# ESP32-H2 register map
Vendor: ESPRESSIF SYSTEMS (SHANGHAI) CO., LTD.; Series: ESP32 H-Series; File version: 12
CPU: RV32IMAC r0p0, little endian, no MPU, no FPU, 0 interrupt priority bits
Address unit: 32 bits
Registers are 32-bit, read-write, reset 0x0 unless marked. A register's access mark holds for its fields unless they carry their own. Offsets are from the block's base; [hi:lo] are bit positions; {n}, {i} and the like mark numbered series.

## EFUSE — eFuse Controller
Base 0x600B0800
0x00 PGM_DATA0 — Register 0 that stores data to be programmed.
  [31:0] PGM_DATA_0 — Configures the 0th 32-bit data to be programmed.
0x04 PGM_DATA1 — Register 1 that stores data to be programmed.
  [31:0] PGM_DATA_1 — Configures the 1st 32-bit data to be programmed.
0x08 PGM_DATA2 — Register 2 that stores data to be programmed.
  [31:0] PGM_DATA_2 — Configures the 2nd 32-bit data to be programmed.
0x0C PGM_DATA3 — Register 3 that stores data to be programmed.
  [31:0] PGM_DATA_3 — Configures the 3rd 32-bit data to be programmed.
{0x0+4i} PGM_DATA{i} (i=4..7) — Register {i} that stores data to be programmed.
  [31:0] PGM_DATA_{i} — Configures the {i}th 32-bit data to be programmed.
0x20 PGM_CHECK_VALUE0 — Register 0 that stores the RS code to be programmed.
  [31:0] PGM_RS_DATA_0 — Configures the 0th 32-bit RS code to be programmed.
0x24 PGM_CHECK_VALUE1 — Register 1 that stores the RS code to be programmed.
  [31:0] PGM_RS_DATA_1 — Configures the 1st 32-bit RS code to be programmed.
0x28 PGM_CHECK_VALUE2 — Register 2 that stores the RS code to be programmed.
  [31:0] PGM_RS_DATA_2 — Configures the 2nd 32-bit RS code to be programmed.
0x2C RD_WR_DIS ro — BLOCK0 data register 0.
  [31:0] WR_DIS — Represents whether programming of individual eFuse memory bit is disabled or enabled. 1: Disabled. 0 Enabled.
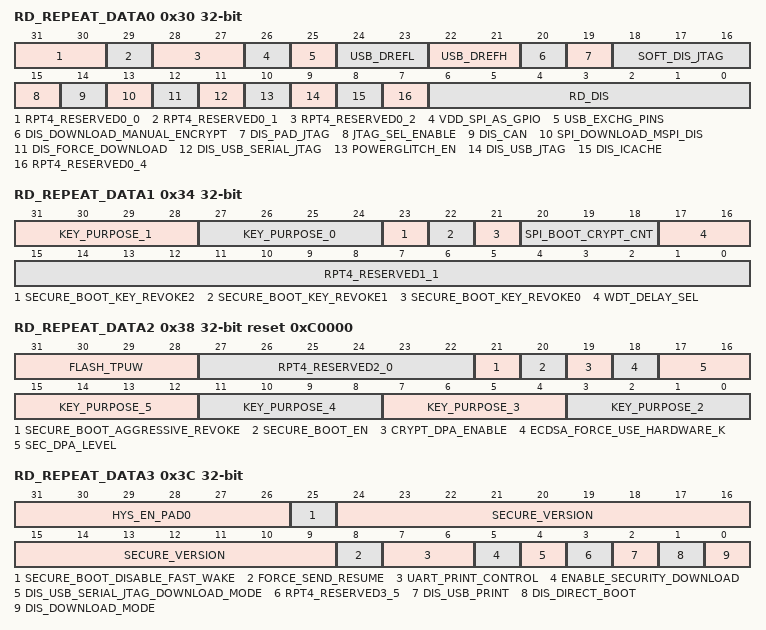
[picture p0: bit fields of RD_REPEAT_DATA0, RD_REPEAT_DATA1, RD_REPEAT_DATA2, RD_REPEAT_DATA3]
0x30 RD_REPEAT_DATA0 ro — BLOCK0 data register 1.
  [31:30] RPT4_RESERVED0_0 — Reserved.
  [29] RPT4_RESERVED0_1 — Reserved.
  [28:27] RPT4_RESERVED0_2 — Reserved.
  [26] VDD_SPI_AS_GPIO — Represents whether vdd spi pin is functioned as gpio. 1: functioned. 0: not functioned.
  [25] USB_EXCHG_PINS — Represents whether the D+ and D- pins is exchanged. 1: exchanged. 0: not exchanged.
  [24:23] USB_DREFL — Represents the single-end input threhold vrefl, 1.76 V to 2 V with step of 80 mV.
  [22:21] USB_DREFH — Represents the single-end input threhold vrefh, 1.76 V to 2 V with step of 80 mV.
  [20] DIS_DOWNLOAD_MANUAL_ENCRYPT — Represents whether flash encrypt function is disabled or enabled(except in SPI boot mode). 1: disabled. 0: enabled.
  [19] DIS_PAD_JTAG — Represents whether JTAG is disabled in the hard way(permanently). 1: disabled. 0: enabled.
  [18:16] SOFT_DIS_JTAG — Represents whether JTAG is disabled in soft way. Odd number: disabled. Even number: enabled.
  [15] JTAG_SEL_ENABLE — Represents whether the selection between usb_to_jtag and pad_to_jtag through strapping gpio15 when both EFUSE_DIS_PAD_JTAG and EFUSE_DIS_USB_JTAG are equal to 0 is enabled or disabled. 1: enabled. 0: disabled.
  [14] DIS_CAN — Represents whether TWAI function is disabled or enabled. 1: disabled. 0: enabled.
  [13] SPI_DOWNLOAD_MSPI_DIS — Represents whether SPI0 controller during boot_mode_download is disabled or enabled. 1: disabled. 0: enabled.
  [12] DIS_FORCE_DOWNLOAD — Represents whether the function that forces chip into download mode is disabled or enabled. 1: disabled. 0: enabled.
  [11] DIS_USB_SERIAL_JTAG — Represents whether USB-Serial-JTAG is disabled or enabled. 1: disabled. 0: enabled.
  [10] POWERGLITCH_EN — Represents whether power glitch function is enabled. 1: enabled. 0: disabled.
  [9] DIS_USB_JTAG — Represents whether the function of usb switch to jtag is disabled or enabled. 1: disabled. 0: enabled.
  [8] DIS_ICACHE — Represents whether icache is disabled or enabled. 1: disabled. 0: enabled.
  [7] RPT4_RESERVED0_4 — Reserved.
  [6:0] RD_DIS — Represents whether reading of individual eFuse block(block4~block10) is disabled or enabled. 1: disabled. 0: enabled.
0x34 RD_REPEAT_DATA1 ro — BLOCK0 data register 2.
  [31:28] KEY_PURPOSE_1 — Represents the purpose of Key1.
  [27:24] KEY_PURPOSE_0 — Represents the purpose of Key0.
  [23] SECURE_BOOT_KEY_REVOKE2 — Represents whether revoking third secure boot key is enabled or disabled. 1: enabled. 0: disabled.
  [22] SECURE_BOOT_KEY_REVOKE1 — Represents whether revoking second secure boot key is enabled or disabled. 1: enabled. 0: disabled.
  [21] SECURE_BOOT_KEY_REVOKE0 — Represents whether revoking first secure boot key is enabled or disabled. 1: enabled. 0: disabled.
  [20:18] SPI_BOOT_CRYPT_CNT — Represents whether SPI boot encrypt/decrypt is disabled or enabled. Odd number of 1: enabled. Even number of 1: disabled.
  [17:16] WDT_DELAY_SEL — Represents whether RTC watchdog timeout threshold is selected at startup. 1: selected. 0: not selected.
  [15:0] RPT4_RESERVED1_1 — Reserved.
0x38 RD_REPEAT_DATA2 ro reset 0xC0000 — BLOCK0 data register 3.
  [31:28] FLASH_TPUW — Represents the flash waiting time after power-up, in unit of ms. When the value less than 15, the waiting time is the programmed value. Otherwise, the waiting time is 2 times the programmed value.
  [27:22] RPT4_RESERVED2_0 — Reserved.
  [21] SECURE_BOOT_AGGRESSIVE_REVOKE — Represents whether revoking aggressive secure boot is enabled or disabled. 1: enabled. 0: disabled.
  [20] SECURE_BOOT_EN — Represents whether secure boot is enabled or disabled. 1: enabled. 0: disabled.
  [19] CRYPT_DPA_ENABLE — Represents whether anti-dpa attack is enabled. 1:enabled. 0: disabled.
  [18] ECDSA_FORCE_USE_HARDWARE_K — Represents whether hardware random number k is forced used in ESDCA. 1: force used. 0: not force used.
  [17:16] SEC_DPA_LEVEL — Represents the spa secure level by configuring the clock random divide mode.
  [4n-5:4n-8] KEY_PURPOSE_{n} (n=2..5) — Represents the purpose of Key{n}.
0x3C RD_REPEAT_DATA3 ro — BLOCK0 data register 4.
  [31:26] HYS_EN_PAD0 — Represents whether the hysteresis function of corresponding PAD is enabled. 1: enabled. 0:disabled.
  [25] SECURE_BOOT_DISABLE_FAST_WAKE — Represents whether FAST VERIFY ON WAKE is disabled or enabled when Secure Boot is enabled. 1: disabled. 0: enabled.
  [24:9] SECURE_VERSION — Represents the version used by ESP-IDF anti-rollback feature.
  [8] FORCE_SEND_RESUME — Represents whether ROM code is forced to send a resume command during SPI boot. 1: forced. 0:not forced.
  [7:6] UART_PRINT_CONTROL — Represents the type of UART printing. 00: force enable printing. 01: enable printing when GPIO8 is reset at low level. 10: enable printing when GPIO8 is reset at high level. 11: force disable printing.
  [5] ENABLE_SECURITY_DOWNLOAD — Represents whether security download is enabled or disabled. 1: enabled. 0: disabled.
  [4] DIS_USB_SERIAL_JTAG_DOWNLOAD_MODE — Represents whether the USB-Serial-JTAG download function is disabled or enabled. 1: disabled. 0: enabled.
  [3] RPT4_RESERVED3_5 — Reserved.
  [2] DIS_USB_PRINT — Represents whether print from USB-Serial-JTAG is disabled or enabled. 1: disabled. 0: enabled.
  [1] DIS_DIRECT_BOOT — Represents whether direct boot mode is disabled or enabled. 1: disabled. 0: enabled.
  [0] DIS_DOWNLOAD_MODE — Represents whether Download mode is disabled or enabled. 1: disabled. 0: enabled.
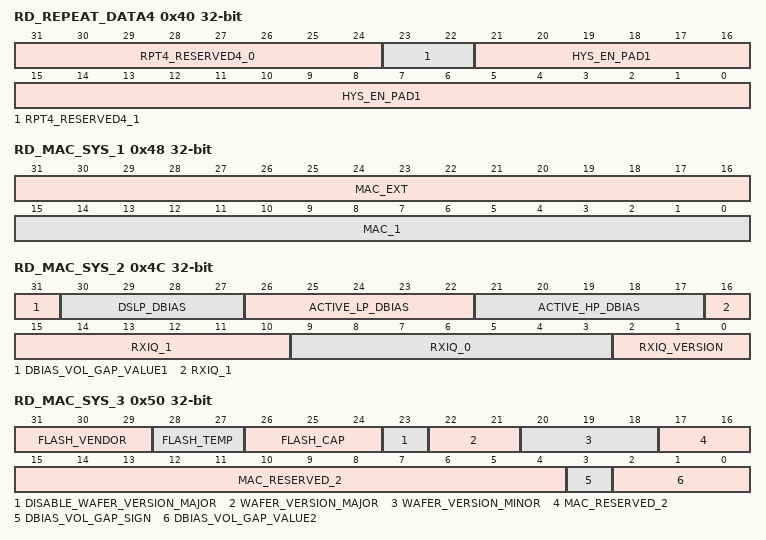
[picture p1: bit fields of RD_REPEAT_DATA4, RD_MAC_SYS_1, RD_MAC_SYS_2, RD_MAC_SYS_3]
0x40 RD_REPEAT_DATA4 ro — BLOCK0 data register 5.
  [31:24] RPT4_RESERVED4_0 — Reserved.
  [23:22] RPT4_RESERVED4_1 — Reserved.
  [21:0] HYS_EN_PAD1 — Represents whether the hysteresis function of corresponding PAD is enabled. 1: enabled. 0:disabled.
0x44 RD_MAC_SYS_0 ro — BLOCK1 data register $n.
  [31:0] MAC_0 — Stores the low 32 bits of MAC address.
0x48 RD_MAC_SYS_1 ro — BLOCK1 data register $n.
  [31:16] MAC_EXT — Stores the extended bits of MAC address.
  [15:0] MAC_1 — Stores the high 16 bits of MAC address.
0x4C RD_MAC_SYS_2 ro — BLOCK1 data register $n.
  [31] DBIAS_VOL_GAP_VALUE1 — Stores the low 1 bit of dbias_vol_gap.
  [30:27] DSLP_DBIAS — Stores the PMU sleep dbias.
  [26:22] ACTIVE_LP_DBIAS — Stores the PMU active lp dbias.
  [21:17] ACTIVE_HP_DBIAS — Stores the PMU active hp dbias.
  [16:10] RXIQ_1 — Stores RF Calibration data. RXIQ data 1.
  [9:3] RXIQ_0 — Stores RF Calibration data. RXIQ data 0.
  [2:0] RXIQ_VERSION — Stores RF Calibration data. RXIQ version.
0x50 RD_MAC_SYS_3 ro — BLOCK1 data register $n.
  [31:29] FLASH_VENDOR — Stores the flash vendor.
  [28:27] FLASH_TEMP — Stores the flash temp.
  [26:24] FLASH_CAP — Stores the flash cap.
  [23] DISABLE_WAFER_VERSION_MAJOR — Disables check of wafer version major.
  [22:21] WAFER_VERSION_MAJOR — Stores the wafer version major.
  [20:18] WAFER_VERSION_MINOR — Stores the wafer version minor.
  [17:4] MAC_RESERVED_2 — Reserved.
  [3] DBIAS_VOL_GAP_SIGN — Stores the sign bit of dbias_vol_gap.
  [2:0] DBIAS_VOL_GAP_VALUE2 — Stores the high 3 bits of dbias_vol_gap.
0x54 RD_MAC_SYS_4 ro — BLOCK1 data register $n.
  [31:0] SYS_DATA_PART0_1 — Stores the first 32 bits of the zeroth part of system data.
0x58 RD_MAC_SYS_5 ro — BLOCK1 data register $n.
  [31:0] SYS_DATA_PART0_2 — Stores the second 32 bits of the zeroth part of system data.
0x5C RD_SYS_PART1_DATA0 ro — Register $n of BLOCK2 (system).
  [31:0] SYS_DATA_PART1_0 — Stores the zeroth 32 bits of the first part of system data.
0x60 RD_SYS_PART1_DATA1 ro — Register $n of BLOCK2 (system).
  [31:0] SYS_DATA_PART1_1 — Stores the first 32 bits of the first part of system data.
0x64 RD_SYS_PART1_DATA2 ro — Register $n of BLOCK2 (system).
  [31:0] SYS_DATA_PART1_2 — Stores the second 32 bits of the first part of system data.
0x68 RD_SYS_PART1_DATA3 ro — Register $n of BLOCK2 (system).
  [31:0] SYS_DATA_PART1_3 — Stores the third 32 bits of the first part of system data.
0x6C RD_SYS_PART1_DATA4 ro — Register $n of BLOCK2 (system).
  [31:0] SYS_DATA_PART1_4 — Stores the fourth 32 bits of the first part of system data.
0x70 RD_SYS_PART1_DATA5 ro — Register $n of BLOCK2 (system).
  [31:0] SYS_DATA_PART1_5 — Stores the fifth 32 bits of the first part of system data.
0x74 RD_SYS_PART1_DATA6 ro — Register $n of BLOCK2 (system).
  [31:0] SYS_DATA_PART1_6 — Stores the sixth 32 bits of the first part of system data.
0x78 RD_SYS_PART1_DATA7 ro — Register $n of BLOCK2 (system).
  [31:0] SYS_DATA_PART1_7 — Stores the seventh 32 bits of the first part of system data.
0x7C RD_USR_DATA0 ro — Register $n of BLOCK3 (user).
  [31:0] USR_DATA0 — Stores the zeroth 32 bits of BLOCK3 (user).
0x80 RD_USR_DATA1 ro — Register $n of BLOCK3 (user).
  [31:0] USR_DATA1 — Stores the first 32 bits of BLOCK3 (user).
0x84 RD_USR_DATA2 ro — Register $n of BLOCK3 (user).
  [31:0] USR_DATA2 — Stores the second 32 bits of BLOCK3 (user).
0x88 RD_USR_DATA3 ro — Register $n of BLOCK3 (user).
  [31:0] USR_DATA3 — Stores the third 32 bits of BLOCK3 (user).
0x8C RD_USR_DATA4 ro — Register $n of BLOCK3 (user).
  [31:0] USR_DATA4 — Stores the fourth 32 bits of BLOCK3 (user).
0x90 RD_USR_DATA5 ro — Register $n of BLOCK3 (user).
  [31:0] USR_DATA5 — Stores the fifth 32 bits of BLOCK3 (user).
0x94 RD_USR_DATA6 ro — Register $n of BLOCK3 (user).
  [31:0] USR_DATA6 — Stores the sixth 32 bits of BLOCK3 (user).
0x98 RD_USR_DATA7 ro — Register $n of BLOCK3 (user).
  [31:0] USR_DATA7 — Stores the seventh 32 bits of BLOCK3 (user).
{0x9C+0x20*i} RD_KEY{i}_DATA0 ro (i=0..5) — Register $n of BLOCK{i+4} (KEY{i}).
  [31:0] KEY{i}_DATA0 — Stores the zeroth 32 bits of KEY{i}.
{0xA0+0x20*i} RD_KEY{i}_DATA1 ro (i=0..5) — Register $n of BLOCK{i+4} (KEY{i}).
  [31:0] KEY{i}_DATA1 — Stores the first 32 bits of KEY{i}.
{0xA4+0x20*i} RD_KEY{i}_DATA2 ro (i=0..5) — Register $n of BLOCK{i+4} (KEY{i}).
  [31:0] KEY{i}_DATA2 — Stores the second 32 bits of KEY{i}.
{0xA8+0x20*i} RD_KEY{i}_DATA3 ro (i=0..5) — Register $n of BLOCK{i+4} (KEY{i}).
  [31:0] KEY{i}_DATA3 — Stores the third 32 bits of KEY{i}.
{0xAC+0x20*i} RD_KEY{i}_DATA4 ro (i=0..5) — Register $n of BLOCK{i+4} (KEY{i}).
  [31:0] KEY{i}_DATA4 — Stores the fourth 32 bits of KEY{i}.
{0xB0+0x20*i} RD_KEY{i}_DATA5 ro (i=0..5) — Register $n of BLOCK{i+4} (KEY{i}).
  [31:0] KEY{i}_DATA5 — Stores the fifth 32 bits of KEY{i}.
{0xB4+0x20*i} RD_KEY{i}_DATA6 ro (i=0..5) — Register $n of BLOCK{i+4} (KEY{i}).
  [31:0] KEY{i}_DATA6 — Stores the sixth 32 bits of KEY{i}.
{0xB8+0x20*i} RD_KEY{i}_DATA7 ro (i=0..5) — Register $n of BLOCK{i+4} (KEY{i}).
  [31:0] KEY{i}_DATA7 — Stores the seventh 32 bits of KEY{i}.
0x15C RD_SYS_PART2_DATA0 ro — Register $n of BLOCK10 (system).
  [31:0] SYS_DATA_PART2_0 — Stores the 0th 32 bits of the 2nd part of system data.
0x160 RD_SYS_PART2_DATA1 ro — Register $n of BLOCK9 (KEY5).
  [31:0] SYS_DATA_PART2_1 — Stores the 0th 32 bits of the 2nd part of system data.
{0x15C+4i} RD_SYS_PART2_DATA{i} ro (i=2..7) — Register $n of BLOCK10 (system).
  [31:0] SYS_DATA_PART2_{i} — Stores the 0th 32 bits of the 2nd part of system data.
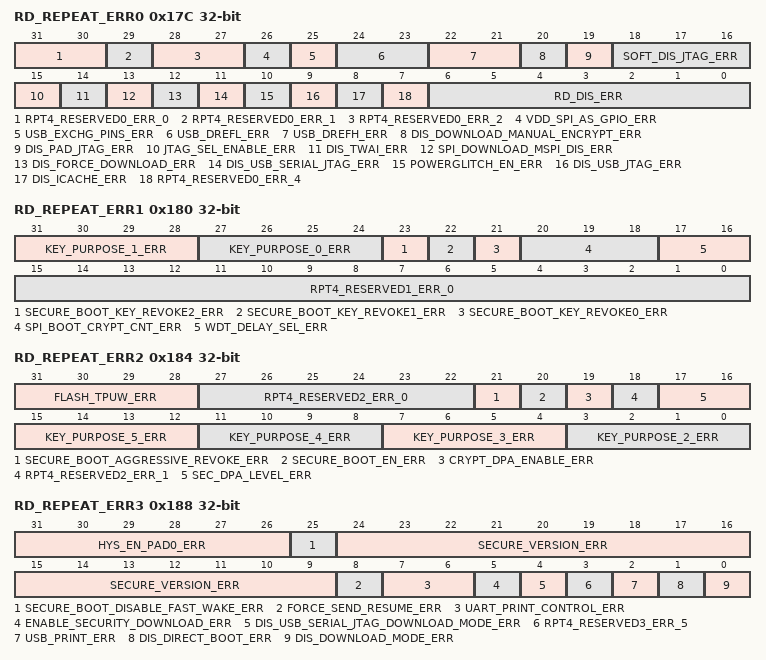
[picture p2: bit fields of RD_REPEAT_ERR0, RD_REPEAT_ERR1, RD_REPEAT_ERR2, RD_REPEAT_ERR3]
0x17C RD_REPEAT_ERR0 ro — Programming error record register 0 of BLOCK0.
  [31:30] RPT4_RESERVED0_ERR_0 — Reserved.
  [29] RPT4_RESERVED0_ERR_1 — Reserved.
  [28:27] RPT4_RESERVED0_ERR_2 — Reserved.
  [26] VDD_SPI_AS_GPIO_ERR — Indicates a programming error of VDD_SPI_AS_GPIO.
  [25] USB_EXCHG_PINS_ERR — Indicates a programming error of USB_EXCHG_PINS.
  [24:23] USB_DREFL_ERR — Indicates a programming error of USB_DREFL.
  [22:21] USB_DREFH_ERR — Indicates a programming error of USB_DREFH.
  [20] DIS_DOWNLOAD_MANUAL_ENCRYPT_ERR — Indicates a programming error of DIS_DOWNLOAD_MANUAL_ENCRYPT.
  [19] DIS_PAD_JTAG_ERR — Indicates a programming error of DIS_PAD_JTAG.
  [18:16] SOFT_DIS_JTAG_ERR — Indicates a programming error of SOFT_DIS_JTAG.
  [15] JTAG_SEL_ENABLE_ERR — Indicates a programming error of JTAG_SEL_ENABLE.
  [14] DIS_TWAI_ERR — Indicates a programming error of DIS_CAN.
  [13] SPI_DOWNLOAD_MSPI_DIS_ERR — Indicates a programming error of SPI_DOWNLOAD_MSPI_DIS.
  [12] DIS_FORCE_DOWNLOAD_ERR — Indicates a programming error of DIS_FORCE_DOWNLOAD.
  [11] DIS_USB_SERIAL_JTAG_ERR — Indicates a programming error of DIS_USB_DEVICE.
  [10] POWERGLITCH_EN_ERR — Indicates a programming error of POWERGLITCH_EN.
  [9] DIS_USB_JTAG_ERR — Indicates a programming error of DIS_USB_JTAG.
  [8] DIS_ICACHE_ERR — Indicates a programming error of DIS_ICACHE.
  [7] RPT4_RESERVED0_ERR_4 — Reserved.
  [6:0] RD_DIS_ERR — Indicates a programming error of RD_DIS.
0x180 RD_REPEAT_ERR1 ro — Programming error record register 1 of BLOCK0.
  [31:28] KEY_PURPOSE_1_ERR — Indicates a programming error of KEY_PURPOSE_1.
  [27:24] KEY_PURPOSE_0_ERR — Indicates a programming error of KEY_PURPOSE_0.
  [23] SECURE_BOOT_KEY_REVOKE2_ERR — Indicates a programming error of SECURE_BOOT_KEY_REVOKE2.
  [22] SECURE_BOOT_KEY_REVOKE1_ERR — Indicates a programming error of SECURE_BOOT_KEY_REVOKE1.
  [21] SECURE_BOOT_KEY_REVOKE0_ERR — Indicates a programming error of SECURE_BOOT_KEY_REVOKE0.
  [20:18] SPI_BOOT_CRYPT_CNT_ERR — Indicates a programming error of SPI_BOOT_CRYPT_CNT.
  [17:16] WDT_DELAY_SEL_ERR — Indicates a programming error of WDT_DELAY_SEL.
  [15:0] RPT4_RESERVED1_ERR_0 — Reserved.
0x184 RD_REPEAT_ERR2 ro — Programming error record register 2 of BLOCK0.
  [31:28] FLASH_TPUW_ERR — Indicates a programming error of FLASH_TPUW.
  [27:22] RPT4_RESERVED2_ERR_0 — Reserved.
  [21] SECURE_BOOT_AGGRESSIVE_REVOKE_ERR — Indicates a programming error of SECURE_BOOT_AGGRESSIVE_REVOKE.
  [20] SECURE_BOOT_EN_ERR — Indicates a programming error of SECURE_BOOT_EN.
  [19] CRYPT_DPA_ENABLE_ERR — Indicates a programming error of CRYPT_DPA_ENABLE.
  [18] RPT4_RESERVED2_ERR_1 — Reserved.
  [17:16] SEC_DPA_LEVEL_ERR — Indicates a programming error of SEC_DPA_LEVEL.
  [4n-5:4n-8] KEY_PURPOSE_{n}_ERR (n=2..5) — Indicates a programming error of KEY_PURPOSE_{n}.
0x188 RD_REPEAT_ERR3 ro — Programming error record register 3 of BLOCK0.
  [31:26] HYS_EN_PAD0_ERR — Indicates a programming error of HYS_EN_PAD0.
  [25] SECURE_BOOT_DISABLE_FAST_WAKE_ERR — Indicates a programming error of SECURE_BOOT_DISABLE_FAST_WAKE.
  [24:9] SECURE_VERSION_ERR — Indicates a programming error of SECURE VERSION.
  [8] FORCE_SEND_RESUME_ERR — Indicates a programming error of FORCE_SEND_RESUME.
  [7:6] UART_PRINT_CONTROL_ERR — Indicates a programming error of UART_PRINT_CONTROL.
  [5] ENABLE_SECURITY_DOWNLOAD_ERR — Indicates a programming error of ENABLE_SECURITY_DOWNLOAD.
  [4] DIS_USB_SERIAL_JTAG_DOWNLOAD_MODE_ERR — Indicates a programming error of DIS_USB_SERIAL_JTAG_DOWNLOAD_MODE.
  [3] RPT4_RESERVED3_ERR_5 — Reserved.
  [2] USB_PRINT_ERR — Indicates a programming error of UART_PRINT_CHANNEL.
  [1] DIS_DIRECT_BOOT_ERR — Indicates a programming error of DIS_DIRECT_BOOT.
  [0] DIS_DOWNLOAD_MODE_ERR — Indicates a programming error of DIS_DOWNLOAD_MODE.
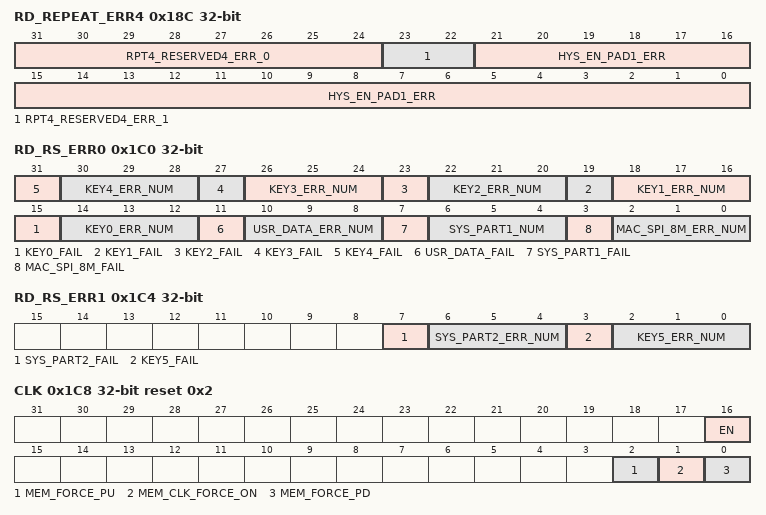
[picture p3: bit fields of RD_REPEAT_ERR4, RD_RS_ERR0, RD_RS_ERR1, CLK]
0x18C RD_REPEAT_ERR4 ro — Programming error record register 4 of BLOCK0.
  [31:24] RPT4_RESERVED4_ERR_0 — Reserved.
  [23:22] RPT4_RESERVED4_ERR_1 — Reserved.
  [21:0] HYS_EN_PAD1_ERR — Indicates a programming error of HYS_EN_PAD1.
0x1C0 RD_RS_ERR0 ro — Programming error record register 0 of BLOCK1-10.
  [4n+15] KEY{n}_FAIL (n=0..4) — 0: Means no failure and that the data of key{n} is reliable 1: Means that programming key{n} failed and the number of error bytes is over 6.
  [4n+14:4n+12] KEY{n}_ERR_NUM (n=0..4) — The value of this signal means the number of error bytes.
  [11] USR_DATA_FAIL — 0: Means no failure and that the user data is reliable 1: Means that programming user data failed and the number of error bytes is over 6.
  [10:8] USR_DATA_ERR_NUM — The value of this signal means the number of error bytes.
  [7] SYS_PART1_FAIL — 0: Means no failure and that the data of system part1 is reliable 1: Means that programming user data failed and the number of error bytes is over 6.
  [6:4] SYS_PART1_NUM — The value of this signal means the number of error bytes.
  [3] MAC_SPI_8M_FAIL — 0: Means no failure and that the data of MAC_SPI_8M is reliable 1: Means that programming user data failed and the number of error bytes is over 6.
  [2:0] MAC_SPI_8M_ERR_NUM — The value of this signal means the number of error bytes.
0x1C4 RD_RS_ERR1 ro — Programming error record register 1 of BLOCK1-10.
  [7] SYS_PART2_FAIL — 0: Means no failure and that the data of system part2 is reliable 1: Means that programming user data failed and the number of error bytes is over 6.
  [6:4] SYS_PART2_ERR_NUM — The value of this signal means the number of error bytes.
  [3] KEY5_FAIL — 0: Means no failure and that the data of key5 is reliable 1: Means that programming key5 failed and the number of error bytes is over 6.
  [2:0] KEY5_ERR_NUM — The value of this signal means the number of error bytes.
0x1C8 CLK reset 0x2 — eFuse clcok configuration register.
  [16] EN — Set this bit to force enable eFuse register configuration clock signal.
  [2] MEM_FORCE_PU — Set this bit to force eFuse SRAM into working mode.
  [1] MEM_CLK_FORCE_ON — Set this bit and force to activate clock signal of eFuse SRAM.
  [0] MEM_FORCE_PD — Set this bit to force eFuse SRAM into power-saving mode.
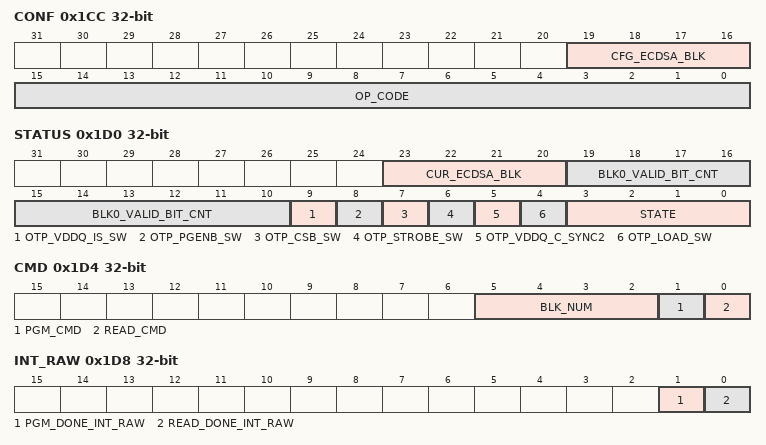
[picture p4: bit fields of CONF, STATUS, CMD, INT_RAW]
0x1CC CONF — eFuse operation mode configuraiton register
  [19:16] CFG_ECDSA_BLK — Configures which block to use for ECDSA key output.
  [15:0] OP_CODE — 0x5A5A: programming operation command 0x5AA5: read operation command.
0x1D0 STATUS ro — eFuse status register.
  [23:20] CUR_ECDSA_BLK — Indicates which block is used for ECDSA key output.
  [19:10] BLK0_VALID_BIT_CNT — Indicates the number of block valid bit.
  [9] OTP_VDDQ_IS_SW — The value of OTP_VDDQ_IS_SW.
  [8] OTP_PGENB_SW — The value of OTP_PGENB_SW.
  [7] OTP_CSB_SW — The value of OTP_CSB_SW.
  [6] OTP_STROBE_SW — The value of OTP_STROBE_SW.
  [5] OTP_VDDQ_C_SYNC2 — The value of OTP_VDDQ_C_SYNC2.
  [4] OTP_LOAD_SW — The value of OTP_LOAD_SW.
  [3:0] STATE — Indicates the state of the eFuse state machine.
0x1D4 CMD — eFuse command register.
  [5:2] BLK_NUM — The serial number of the block to be programmed. Value 0-10 corresponds to block number 0-10, respectively.
  [1] PGM_CMD — Set this bit to send programming command.
  [0] READ_CMD — Set this bit to send read command.
0x1D8 INT_RAW ro — eFuse raw interrupt register.
  [1] PGM_DONE_INT_RAW — The raw bit signal for pgm_done interrupt.
  [0] READ_DONE_INT_RAW — The raw bit signal for read_done interrupt.
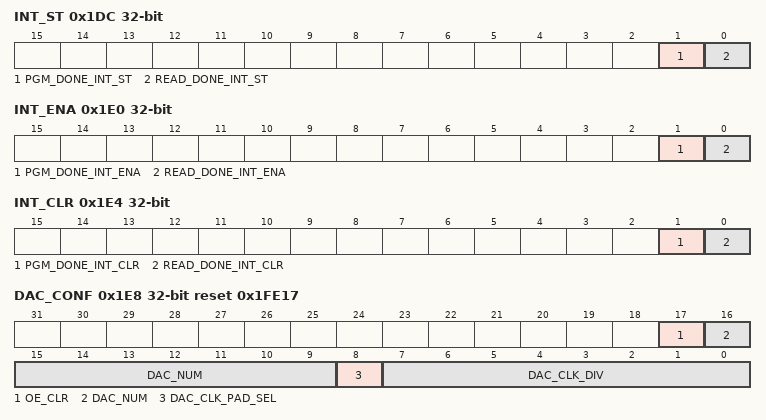
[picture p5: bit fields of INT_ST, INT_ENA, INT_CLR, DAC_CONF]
0x1DC INT_ST ro — eFuse interrupt status register.
  [1] PGM_DONE_INT_ST — The status signal for pgm_done interrupt.
  [0] READ_DONE_INT_ST — The status signal for read_done interrupt.
0x1E0 INT_ENA — eFuse interrupt enable register.
  [1] PGM_DONE_INT_ENA — The enable signal for pgm_done interrupt.
  [0] READ_DONE_INT_ENA — The enable signal for read_done interrupt.
0x1E4 INT_CLR wo — eFuse interrupt clear register.
  [1] PGM_DONE_INT_CLR — The clear signal for pgm_done interrupt.
  [0] READ_DONE_INT_CLR — The clear signal for read_done interrupt.
0x1E8 DAC_CONF reset 0x1FE17 — Controls the eFuse programming voltage.
  [17] OE_CLR — Reduces the power supply of the programming voltage.
  [16:9] DAC_NUM — Controls the rising period of the programming voltage.
  [8] DAC_CLK_PAD_SEL — Don't care.
  [7:0] DAC_CLK_DIV — Controls the division factor of the rising clock of the programming voltage.
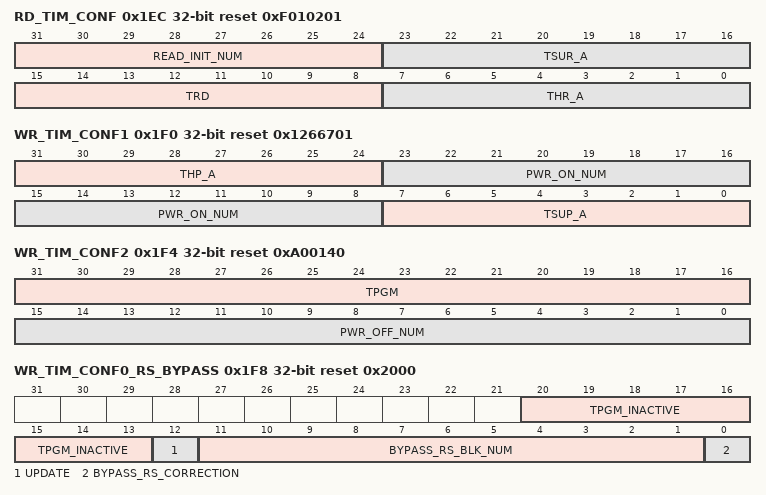
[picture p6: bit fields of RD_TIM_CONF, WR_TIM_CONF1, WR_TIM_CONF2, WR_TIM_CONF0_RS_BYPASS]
0x1EC RD_TIM_CONF reset 0xF010201 — Configures read timing parameters.
  [31:24] READ_INIT_NUM — Configures the waiting time of reading eFuse memory.
  [23:16] TSUR_A — Configures the read setup time.
  [15:8] TRD — Configures the read time.
  [7:0] THR_A — Configures the read hold time.
0x1F0 WR_TIM_CONF1 reset 0x1266701 — Configurarion register 1 of eFuse programming timing parameters.
  [31:24] THP_A — Configures the programming hold time.
  [23:8] PWR_ON_NUM — Configures the power up time for VDDQ.
  [7:0] TSUP_A — Configures the programming setup time.
0x1F4 WR_TIM_CONF2 reset 0xA00140 — Configurarion register 2 of eFuse programming timing parameters.
  [31:16] TPGM — Configures the active programming time.
  [15:0] PWR_OFF_NUM — Configures the power outage time for VDDQ.
0x1F8 WR_TIM_CONF0_RS_BYPASS access per field reset 0x2000 — Configurarion register0 of eFuse programming time parameters and rs bypass operation.
  [20:13] TPGM_INACTIVE rw — Configures the inactive programming time.
  [12] UPDATE wo — Set this bit to update multi-bit register signals.
  [11:1] BYPASS_RS_BLK_NUM rw — Configures block number of programming twice operation.
  [0] BYPASS_RS_CORRECTION rw — Set this bit to bypass reed solomon correction step.
0x1FC DATE reset 0x2208120 — eFuse version register.
  [27:0] DATE — Stores eFuse version.

## Notices in the file
Copyright 2025 Espressif Systems (Shanghai) PTE LTD
Licensed under the Apache License, Version 2.0 (the "License");
you may not use this file except in compliance with the License.
You may obtain a copy of the License at
http://www.apache.org/licenses/LICENSE-2.0
Unless required by applicable law or agreed to in writing, software
distributed under the License is distributed on an "AS IS" BASIS,
WITHOUT WARRANTIES OR CONDITIONS OF ANY KIND, either express or implied.
See the License for the specific language governing permissions and
limitations under the License.
